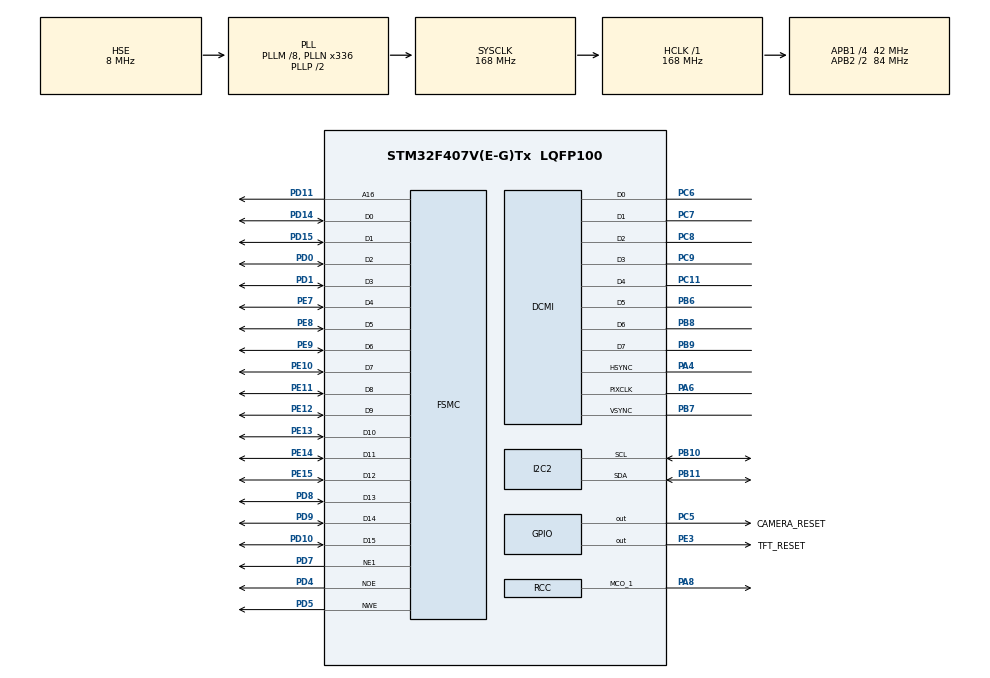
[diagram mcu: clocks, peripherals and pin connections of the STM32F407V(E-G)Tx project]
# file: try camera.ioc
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DCMI.PCKPolarity=DCMI_PCKPOLARITY_RISING
DCMI.VSPolarity=DCMI_VSPOLARITY_HIGH
Dma.DCMI.0.Direction=DMA_PERIPH_TO_MEMORY
Dma.DCMI.0.FIFOMode=DMA_FIFOMODE_DISABLE
Dma.DCMI.0.Instance=DMA2_Stream1
Dma.DCMI.0.MemDataAlignment=DMA_MDATAALIGN_WORD
Dma.DCMI.0.MemInc=DMA_MINC_DISABLE
Dma.DCMI.0.Mode=DMA_NORMAL
Dma.DCMI.0.PeriphDataAlignment=DMA_PDATAALIGN_WORD
Dma.DCMI.0.PeriphInc=DMA_PINC_DISABLE
Dma.DCMI.0.Priority=DMA_PRIORITY_LOW
Dma.Request0=DCMI
FSMC.AddressSetupTime1=4
FSMC.BusTurnAroundDuration1=1
FSMC.DataSetupTime1=8
Mcu.Family=STM32F4
Mcu.Name=STM32F407V(E-G)Tx
Mcu.Package=LQFP100
NVIC.DCMI_IRQn=true\:0\:0\:false\:false\:true\:true\:true\:true
NVIC.DMA2_Stream1_IRQn=true\:0\:0\:false\:false\:true\:false\:true\:true
NVIC.PriorityGroup=NVIC_PRIORITYGROUP_0
PA4.GPIO_PuPd=GPIO_PULLDOWN
PA4.GPIO_Speed=GPIO_SPEED_FREQ_VERY_HIGH
PA4.Mode=Slave_8_bits_External_Synchro
PA4.Signal=DCMI_HSYNC
PA6.GPIO_PuPd=GPIO_PULLDOWN
PA6.GPIO_Speed=GPIO_SPEED_FREQ_VERY_HIGH
PA6.Mode=Slave_8_bits_External_Synchro
PA6.Signal=DCMI_PIXCLK
PA8.GPIO_Speed=GPIO_SPEED_FREQ_VERY_HIGH
PA8.Mode=Clock-out-1
PA8.Signal=RCC_MCO_1
PB10.GPIO_Pu=GPIO_PULLUP
PB10.Mode=I2C
PB10.Signal=I2C2_SCL
PB11.GPIO_Pu=GPIO_PULLUP
PB11.Mode=I2C
PB11.Signal=I2C2_SDA
PB6.GPIO_PuPd=GPIO_PULLDOWN
PB6.GPIO_Speed=GPIO_SPEED_FREQ_VERY_HIGH
PB6.Mode=Slave_8_bits_External_Synchro
PB6.Signal=DCMI_D5
PB7.GPIO_PuPd=GPIO_PULLDOWN
PB7.GPIO_Speed=GPIO_SPEED_FREQ_VERY_HIGH
PB7.Mode=Slave_8_bits_External_Synchro
PB7.Signal=DCMI_VSYNC
PB8.GPIO_PuPd=GPIO_PULLDOWN
PB8.GPIO_Speed=GPIO_SPEED_FREQ_VERY_HIGH
PB8.Mode=Slave_8_bits_External_Synchro
PB8.Signal=DCMI_D6
PB9.GPIO_PuPd=GPIO_PULLDOWN
PB9.GPIO_Speed=GPIO_SPEED_FREQ_VERY_HIGH
PB9.Mode=Slave_8_bits_External_Synchro
PB9.Signal=DCMI_D7
PC11.GPIO_PuPd=GPIO_PULLDOWN
PC11.GPIO_Speed=GPIO_SPEED_FREQ_VERY_HIGH
PC11.Mode=Slave_8_bits_External_Synchro
PC11.Signal=DCMI_D4
PC5.GPIO_Label=CAMERA_RESET
PC5.GPIO_PuPd=GPIO_PULLUP
PC5.Signal=GPIO_Output
PC6.GPIO_PuPd=GPIO_PULLDOWN
PC6.GPIO_Speed=GPIO_SPEED_FREQ_VERY_HIGH
PC6.Mode=Slave_8_bits_External_Synchro
PC6.Signal=DCMI_D0
PC7.GPIO_PuPd=GPIO_PULLDOWN
PC7.GPIO_Speed=GPIO_SPEED_FREQ_VERY_HIGH
PC7.Mode=Slave_8_bits_External_Synchro
PC7.Signal=DCMI_D1
PC8.GPIO_PuPd=GPIO_PULLDOWN
PC8.GPIO_Speed=GPIO_SPEED_FREQ_VERY_HIGH
PC8.Mode=Slave_8_bits_External_Synchro
PC8.Signal=DCMI_D2
PC9.GPIO_PuPd=GPIO_PULLDOWN
PC9.GPIO_Speed=GPIO_SPEED_FREQ_VERY_HIGH
PC9.Mode=Slave_8_bits_External_Synchro
PC9.Signal=DCMI_D3
PD0.Mode=16b-d1
PD0.Signal=FSMC_D2
PD1.Mode=16b-d1
PD1.Signal=FSMC_D3
PD10.Mode=16b-d1
PD10.Signal=FSMC_D15
PD11.Mode=A16_1
PD11.Signal=FSMC_A16
PD14.Mode=16b-d1
PD14.Signal=FSMC_D0
PD15.Mode=16b-d1
PD15.Signal=FSMC_D1
PD4.Mode=Lcd1
PD4.Signal=FSMC_NOE
PD5.Mode=Lcd1
PD5.Signal=FSMC_NWE
PD7.Mode=NorPsramChipSelect1_1
PD7.Signal=FSMC_NE1
PD8.Mode=16b-d1
PD8.Signal=FSMC_D13
PD9.Mode=16b-d1
PD9.Signal=FSMC_D14
PE10.Mode=16b-d1
PE10.Signal=FSMC_D7
PE11.Mode=16b-d1
PE11.Signal=FSMC_D8
PE12.Mode=16b-d1
PE12.Signal=FSMC_D9
PE13.Mode=16b-d1
PE13.Signal=FSMC_D10
PE14.Mode=16b-d1
PE14.Signal=FSMC_D11
PE15.Mode=16b-d1
PE15.Signal=FSMC_D12
PE3.GPIO_Label=TFT_RESET
PE3.PinState=GPIO_PIN_SET
PE3.Signal=GPIO_Output
PE7.Mode=16b-d1
PE7.Signal=FSMC_D4
PE8.Mode=16b-d1
PE8.Signal=FSMC_D5
PE9.Mode=16b-d1
PE9.Signal=FSMC_D6
PH0-OSC_IN.Mode=HSE-External-Oscillator
PH0-OSC_IN.Signal=RCC_OSC_IN
PH1-OSC_OUT.Mode=HSE-External-Oscillator
PH1-OSC_OUT.Signal=RCC_OSC_OUT
ProjectManager.HeapSize=0x200
ProjectManager.StackSize=0x400
ProjectManager.TargetToolchain=STM32CubeIDE
RCC.48MHZClocksFreq_Value=48000000
RCC.AHBFreq_Value=168000000
RCC.APB1CLKDivider=RCC_HCLK_DIV4
RCC.APB1Freq_Value=42000000
RCC.APB1TimFreq_Value=84000000
RCC.APB2CLKDivider=RCC_HCLK_DIV2
RCC.APB2Freq_Value=84000000
RCC.APB2TimFreq_Value=168000000
RCC.CortexFreq_Value=168000000
RCC.HCLKFreq_Value=168000000
RCC.HSE_VALUE=8000000
RCC.HSI_VALUE=16000000
RCC.LSE_VALUE=32768
RCC.PLLM=8
RCC.PLLN=336
RCC.PLLQ=7
RCC.PLLSourceVirtual=RCC_PLLSOURCE_HSE
RCC.RCC_MCO1Source=RCC_MCO1SOURCE_PLLCLK
RCC.RCC_MCODiv1=RCC_MCODIV_4
RCC.SYSCLKFreq_VALUE=168000000
RCC.SYSCLKSource=RCC_SYSCLKSOURCE_PLLCLK
RCC.VCOOutputFreq_Value=336000000
board=STM32F407G-DISC1

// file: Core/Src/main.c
/* USER CODE BEGIN Header */
/**
  ******************************************************************************
  * @file           : main.c
  * @brief          : Main program body
  ******************************************************************************
  * @attention
  *
  * Copyright (c) 2022 STMicroelectronics.
  * All rights reserved.
  *
  * This software is licensed under terms that can be found in the LICENSE file
  * in the root directory of this software component.
  * If no LICENSE file comes with this software, it is provided AS-IS.
  *
  ******************************************************************************
  */
/* USER CODE END Header */
#include "main.h"

/* USER CODE BEGIN Includes */
#include "common.h"
#include "ssd1289.h"
#include "ov7670.h"
/* USER CODE END Includes */

DCMI_HandleTypeDef hdcmi;
DMA_HandleTypeDef hdma_dcmi;

I2C_HandleTypeDef hi2c2;

SRAM_HandleTypeDef hsram1;

void SystemClock_Config(void);
static void MX_GPIO_Init(void);
static void MX_DMA_Init(void);
static void MX_DCMI_Init(void);
static void MX_FSMC_Init(void);
static void MX_I2C2_Init(void);

int main(void)
{

  /* MCU Configuration--------------------------------------------------------*/

  /* Reset of all peripherals, Initializes the Flash interface and the Systick. */
  HAL_Init();

  /* Configure the system clock */
  SystemClock_Config();

  /* Initialize all configured peripherals */
  MX_GPIO_Init();
  MX_DMA_Init();
  MX_DCMI_Init();
  MX_FSMC_Init();
  MX_I2C2_Init();
  /* USER CODE BEGIN 2 */
  Init_SSD1289();
  uint16_t* p_lcdData;
  p_lcdData = getDrawAddress();
  ov7670_init(&hdcmi, &hdcmi, &hi2c2);
  ov7670_config(OV7670_MODE_QVGA_RGB565);
  ov7670_startCap(OV7670_CAP_CONTINUOUS, p_lcdData);
  /* USER CODE END 2 */

  /* Infinite loop */
  while (1)
  {

  }
}

void SystemClock_Config(void)
{
  RCC_OscInitTypeDef RCC_OscInitStruct = {0};
  RCC_ClkInitTypeDef RCC_ClkInitStruct = {0};

  /** Configure the main internal regulator output voltage
  */
  __HAL_RCC_PWR_CLK_ENABLE();
  __HAL_PWR_VOLTAGESCALING_CONFIG(PWR_REGULATOR_VOLTAGE_SCALE1);

  /** Initializes the RCC Oscillators according to the specified parameters
  * in the RCC_OscInitTypeDef structure.
  */
  RCC_OscInitStruct.OscillatorType = RCC_OSCILLATORTYPE_HSE;
  RCC_OscInitStruct.HSEState = RCC_HSE_ON;
  RCC_OscInitStruct.PLL.PLLState = RCC_PLL_ON;
  RCC_OscInitStruct.PLL.PLLSource = RCC_PLLSOURCE_HSE;
  RCC_OscInitStruct.PLL.PLLM = 8;
  RCC_OscInitStruct.PLL.PLLN = 336;
  RCC_OscInitStruct.PLL.PLLP = RCC_PLLP_DIV2;
  RCC_OscInitStruct.PLL.PLLQ = 7;
  if (HAL_RCC_OscConfig(&RCC_OscInitStruct) != HAL_OK)
  {
    Error_Handler();
  }

  /** Initializes the CPU, AHB and APB buses clocks
  */
  RCC_ClkInitStruct.ClockType = RCC_CLOCKTYPE_HCLK|RCC_CLOCKTYPE_SYSCLK
                              |RCC_CLOCKTYPE_PCLK1|RCC_CLOCKTYPE_PCLK2;
  RCC_ClkInitStruct.SYSCLKSource = RCC_SYSCLKSOURCE_PLLCLK;
  RCC_ClkInitStruct.AHBCLKDivider = RCC_SYSCLK_DIV1;
  RCC_ClkInitStruct.APB1CLKDivider = RCC_HCLK_DIV4;
  RCC_ClkInitStruct.APB2CLKDivider = RCC_HCLK_DIV2;

  if (HAL_RCC_ClockConfig(&RCC_ClkInitStruct, FLASH_LATENCY_5) != HAL_OK)
  {
    Error_Handler();
  }
  HAL_RCC_MCOConfig(RCC_MCO1, RCC_MCO1SOURCE_PLLCLK, RCC_MCODIV_4);
}

static void MX_DCMI_Init(void)
{

  hdcmi.Instance = DCMI;
  hdcmi.Init.SynchroMode = DCMI_SYNCHRO_HARDWARE;
  hdcmi.Init.PCKPolarity = DCMI_PCKPOLARITY_RISING;
  hdcmi.Init.VSPolarity = DCMI_VSPOLARITY_HIGH;
  hdcmi.Init.HSPolarity = DCMI_HSPOLARITY_LOW;
  hdcmi.Init.CaptureRate = DCMI_CR_ALL_FRAME;
  hdcmi.Init.ExtendedDataMode = DCMI_EXTEND_DATA_8B;
  hdcmi.Init.JPEGMode = DCMI_JPEG_DISABLE;
  if (HAL_DCMI_Init(&hdcmi) != HAL_OK)
  {
    Error_Handler();
  }

}

static void MX_I2C2_Init(void)
{

  hi2c2.Instance = I2C2;
  hi2c2.Init.ClockSpeed = 100000;
  hi2c2.Init.DutyCycle = I2C_DUTYCYCLE_2;
  hi2c2.Init.OwnAddress1 = 0;
  hi2c2.Init.AddressingMode = I2C_ADDRESSINGMODE_7BIT;
  hi2c2.Init.DualAddressMode = I2C_DUALADDRESS_DISABLE;
  hi2c2.Init.OwnAddress2 = 0;
  hi2c2.Init.GeneralCallMode = I2C_GENERALCALL_DISABLE;
  hi2c2.Init.NoStretchMode = I2C_NOSTRETCH_DISABLE;
  if (HAL_I2C_Init(&hi2c2) != HAL_OK)
  {
    Error_Handler();
  }

}

static void MX_DMA_Init(void)
{

  /* DMA controller clock enable */
  __HAL_RCC_DMA2_CLK_ENABLE();

  /* DMA interrupt init */
  /* DMA2_Stream1_IRQn interrupt configuration */
  HAL_NVIC_SetPriority(DMA2_Stream1_IRQn, 0, 0);
  HAL_NVIC_EnableIRQ(DMA2_Stream1_IRQn);

}

static void MX_GPIO_Init(void)
{
  GPIO_InitTypeDef GPIO_InitStruct = {0};

  /* GPIO Ports Clock Enable */
  __HAL_RCC_GPIOE_CLK_ENABLE();
  __HAL_RCC_GPIOH_CLK_ENABLE();
  __HAL_RCC_GPIOA_CLK_ENABLE();
  __HAL_RCC_GPIOC_CLK_ENABLE();
  __HAL_RCC_GPIOB_CLK_ENABLE();
  __HAL_RCC_GPIOD_CLK_ENABLE();

  /*Configure GPIO pin Output Level */
  HAL_GPIO_WritePin(TFT_RESET_GPIO_Port, TFT_RESET_Pin, GPIO_PIN_SET);

  /*Configure GPIO pin Output Level */
  HAL_GPIO_WritePin(CAMERA_RESET_GPIO_Port, CAMERA_RESET_Pin, GPIO_PIN_RESET);

  /*Configure GPIO pin : TFT_RESET_Pin */
  GPIO_InitStruct.Pin = TFT_RESET_Pin;
  GPIO_InitStruct.Mode = GPIO_MODE_OUTPUT_PP;
  GPIO_InitStruct.Pull = GPIO_NOPULL;
  GPIO_InitStruct.Speed = GPIO_SPEED_FREQ_LOW;
  HAL_GPIO_Init(TFT_RESET_GPIO_Port, &GPIO_InitStruct);

  /*Configure GPIO pin : CAMERA_RESET_Pin */
  GPIO_InitStruct.Pin = CAMERA_RESET_Pin;
  GPIO_InitStruct.Mode = GPIO_MODE_OUTPUT_PP;
  GPIO_InitStruct.Pull = GPIO_PULLUP;
  GPIO_InitStruct.Speed = GPIO_SPEED_FREQ_LOW;
  HAL_GPIO_Init(CAMERA_RESET_GPIO_Port, &GPIO_InitStruct);

  /*Configure GPIO pin : PA8 */
  GPIO_InitStruct.Pin = GPIO_PIN_8;
  GPIO_InitStruct.Mode = GPIO_MODE_AF_PP;
  GPIO_InitStruct.Pull = GPIO_NOPULL;
  GPIO_InitStruct.Speed = GPIO_SPEED_FREQ_VERY_HIGH;
  GPIO_InitStruct.Alternate = GPIO_AF0_MCO;
  HAL_GPIO_Init(GPIOA, &GPIO_InitStruct);

}

/* FSMC initialization function */
static void MX_FSMC_Init(void)
{

  FSMC_NORSRAM_TimingTypeDef Timing = {0};

  /** Perform the SRAM1 memory initialization sequence
  */
  hsram1.Instance = FSMC_NORSRAM_DEVICE;
  hsram1.Extended = FSMC_NORSRAM_EXTENDED_DEVICE;
  /* hsram1.Init */
  hsram1.Init.NSBank = FSMC_NORSRAM_BANK1;
  hsram1.Init.DataAddressMux = FSMC_DATA_ADDRESS_MUX_DISABLE;
  hsram1.Init.MemoryType = FSMC_MEMORY_TYPE_SRAM;
  hsram1.Init.MemoryDataWidth = FSMC_NORSRAM_MEM_BUS_WIDTH_16;
  hsram1.Init.BurstAccessMode = FSMC_BURST_ACCESS_MODE_DISABLE;
  hsram1.Init.WaitSignalPolarity = FSMC_WAIT_SIGNAL_POLARITY_LOW;
  hsram1.Init.WrapMode = FSMC_WRAP_MODE_DISABLE;
  hsram1.Init.WaitSignalActive = FSMC_WAIT_TIMING_BEFORE_WS;
  hsram1.Init.WriteOperation = FSMC_WRITE_OPERATION_ENABLE;
  hsram1.Init.WaitSignal = FSMC_WAIT_SIGNAL_DISABLE;
  hsram1.Init.ExtendedMode = FSMC_EXTENDED_MODE_DISABLE;
  hsram1.Init.AsynchronousWait = FSMC_ASYNCHRONOUS_WAIT_DISABLE;
  hsram1.Init.WriteBurst = FSMC_WRITE_BURST_DISABLE;
  hsram1.Init.PageSize = FSMC_PAGE_SIZE_NONE;
  /* Timing */
  Timing.AddressSetupTime = 4;
  Timing.AddressHoldTime = 15;
  Timing.DataSetupTime = 8;
  Timing.BusTurnAroundDuration = 1;
  Timing.CLKDivision = 16;
  Timing.DataLatency = 17;
  Timing.AccessMode = FSMC_ACCESS_MODE_A;
  /* ExtTiming */

  if (HAL_SRAM_Init(&hsram1, &Timing, NULL) != HAL_OK)
  {
    Error_Handler( );
  }

}

void Error_Handler(void)
{
  __disable_irq();
  while (1)
  {
  }
}
